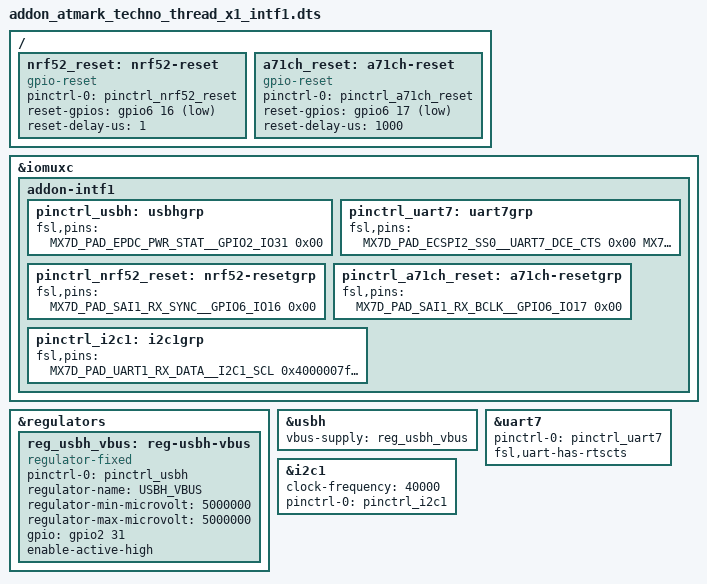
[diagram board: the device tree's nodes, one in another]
/*
 * Copyright (C) 2019 Atmark Techno, Inc. All Rights Reserved.
 * Author: Daisuke Mizobuchi <mizo@atmark-techno.com>
 *
 * This program is free software; you can redistribute it and/or
 * modify it under the terms of the GNU General Public License
 * version 2 as published by the Free Software Foundation.
 */

#include <dt-bindings/clock/imx7d-clock.h>
#include "../../../../arch/arm/boot/dts/imx7d-pinfunc.h"

/dts-v1/;
/plugin/;
/ {
	fragment@0 {
		target = <&iomuxc>;
		__overlay__ {
			addon-intf1 {
				pinctrl_usbh: usbhgrp {
					fsl,pins = <
						MX7D_PAD_EPDC_PWR_STAT__GPIO2_IO31 0x00	/* G_AOM_USB_PWREN */
					>;
				};
				pinctrl_uart7: uart7grp {
					fsl,pins = <
						MX7D_PAD_ECSPI2_SS0__UART7_DCE_CTS	0x00	/* INTF1_38 */
						MX7D_PAD_ECSPI2_MISO__UART7_DCE_RTS	0x70	/* INTF1_39 */
						MX7D_PAD_ECSPI2_MOSI__UART7_DCE_TX	0x00	/* INTF1_40 */
						MX7D_PAD_ECSPI2_SCLK__UART7_DCE_RX	0x70	/* INTF1_41 */
					>;
				};
				pinctrl_nrf52_reset: nrf52-resetgrp {
					fsl,pins = <
						MX7D_PAD_SAI1_RX_SYNC__GPIO6_IO16	0x00	/* INTF1_42 */
					>;
				};
				pinctrl_a71ch_reset: a71ch-resetgrp {
					fsl,pins = <
						MX7D_PAD_SAI1_RX_BCLK__GPIO6_IO17	0x00	/* INTF1_43 */
					>;
				};
				pinctrl_i2c1: i2c1grp {
					fsl,pins = <
						MX7D_PAD_UART1_RX_DATA__I2C1_SCL	0x4000007f /* INTF1_24 */
						MX7D_PAD_UART1_TX_DATA__I2C1_SDA	0x4000007f /* INTF1_25 */
					>;
				};
			};
		};
	};

	fragment@1 {
		target = <&regulators>;
		__overlay__ {
			reg_usbh_vbus: reg-usbh-vbus {
				compatible = "regulator-fixed";
				pinctrl-names = "default";
				pinctrl-0 = <&pinctrl_usbh>;
				regulator-name = "USBH_VBUS";
				regulator-min-microvolt = <5000000>;
				regulator-max-microvolt = <5000000>;
				gpio = <&gpio2 31 0>;
				enable-active-high;
			};
		};
	};

	fragment@2 {
		target = <&usbh>;
		__overlay__ {
			vbus-supply = <&reg_usbh_vbus>;
		};
	};

	fragment@3 {
		target = <&uart7>;
		__overlay__ {
			pinctrl-names = "default";
			pinctrl-0 = <&pinctrl_uart7>;
			fsl,uart-has-rtscts;
			status = "okay";
		};
	};

	fragment@4 {
		target-path = "/";
		__overlay__ {
			nrf52_reset: nrf52-reset {
				compatible = "gpio-reset";
				pinctrl-0 = <&pinctrl_nrf52_reset>;
				reset-gpios = <&gpio6 16 1>;
				reset-delay-us = <1>;
				#reset-cells = <2>;
			};

			a71ch_reset: a71ch-reset {
				compatible = "gpio-reset";
				pinctrl-0 = <&pinctrl_a71ch_reset>;
				reset-gpios = <&gpio6 17 1>;
				reset-delay-us = <1000>;
				#reset-cells = <2>;
			};
		};
	};

	fragment@5 {
		target = <&i2c1>;
		__overlay__ {
			clock-frequency = <40000>;
			pinctrl-names = "default";
			pinctrl-0 = <&pinctrl_i2c1>;
			status = "okay";
		};
	};
};
